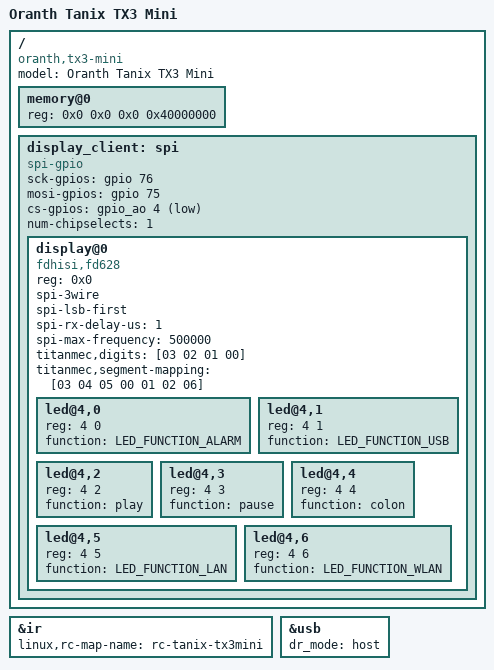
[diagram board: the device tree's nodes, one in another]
// SPDX-License-Identifier: (GPL-2.0+ OR MIT)
/*
 * Copyright (c) 2018 Martin Blumenstingl <martin.blumenstingl@googlemail.com>.
 * Based on meson-gxl-s905d-p231.dts:
 * - Copyright (c) 2016 Endless Computers, Inc.
 *   Author: Carlo Caione <carlo@endlessm.com>
 */

/dts-v1/;

#include "meson-gxl-s905x.dtsi"
#include "meson-gx-p23x-q20x.dtsi"
#include <dt-bindings/gpio/gpio.h>
#include <dt-bindings/leds/common.h>

/ {
	compatible = "oranth,tx3-mini", "amlogic,s905w", "amlogic,meson-gxl";
	model = "Oranth Tanix TX3 Mini";

	memory@0 {
		device_type = "memory";
		reg = <0x0 0x0 0x0 0x40000000>; /* 1 GiB or 2 GiB */
	};

	display_client: spi {
		compatible = "spi-gpio";
		sck-gpios = <&gpio 76 GPIO_ACTIVE_HIGH>;
		mosi-gpios = <&gpio 75 GPIO_ACTIVE_HIGH>;
		cs-gpios = <&gpio_ao 4 GPIO_ACTIVE_LOW>;
		num-chipselects = <1>;

		#address-cells = <1>;
		#size-cells = <0>;

		display@0 {
			compatible = "fdhisi,fd628";
			reg = <0x0>;
			spi-3wire;
			spi-lsb-first;
			spi-rx-delay-us = <1>;
			spi-max-frequency = <500000>;

			titanmec,digits = [03 02 01 00];
			titanmec,segment-mapping = [03 04 05 00 01 02 06];

			#address-cells = <2>;
			#size-cells = <0>;

			led@4,0 {
				reg = <4 0>;
				function = LED_FUNCTION_ALARM;
			};

			led@4,1 {
				reg = <4 1>;
				function = LED_FUNCTION_USB;
			};

			led@4,2 {
				reg = <4 2>;
				function = "play";
			};

			led@4,3 {
				reg = <4 3>;
				function = "pause";
			};

			led@4,4 {
				reg = <4 4>;
				function = "colon";
			};

			led@4,5 {
				reg = <4 5>;
				function = LED_FUNCTION_LAN;
			};

			led@4,6 {
				reg = <4 6>;
				function = LED_FUNCTION_WLAN;
			};
		};
	};
};

&ir {
	linux,rc-map-name = "rc-tanix-tx3mini";
};

&usb {
	dr_mode = "host";
};
